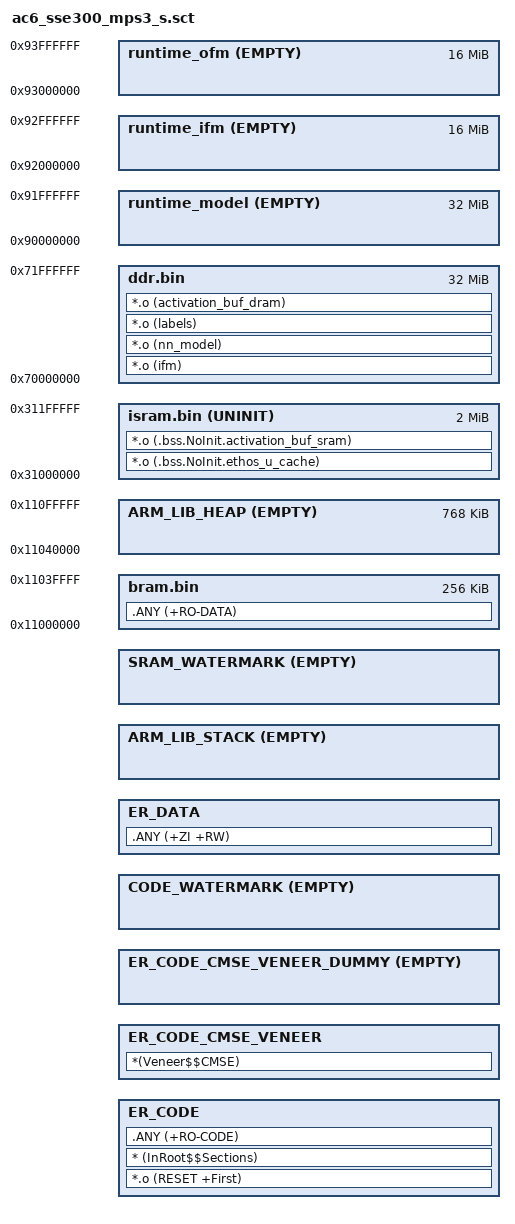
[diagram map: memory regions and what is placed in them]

;/*
; * Copyright (c) 2018-2021 Arm Limited. All rights reserved.
; *
; * Licensed under the Apache License, Version 2.0 (the "License");
; * you may not use this file except in compliance with the License.
; * You may obtain a copy of the License at
; *
; *     http://www.apache.org/licenses/LICENSE-2.0
; *
; * Unless required by applicable law or agreed to in writing, software
; * distributed under the License is distributed on an "AS IS" BASIS,
; * WITHOUT WARRANTIES OR CONDITIONS OF ANY KIND, either express or implied.
; * See the License for the specific language governing permissions and
; * limitations under the License.
; *
; */

;#include "region_defs.h"

LR_CODE S_CODE_START {
    ER_CODE S_CODE_START {
        *.o (RESET +First)
        /* different test vectors */
        * (InRoot$$Sections)
        .ANY (+RO-CODE)
        
    }

    /*
     * Place the CMSE Veneers (containing the SG instruction) after the code, in
     * a separate 32 bytes aligned region so that the SAU can programmed to just
     * set this region as Non-Secure Callable. The maximum size of this
     * executable region makes it only used the space left over by the ER_CODE
     * region so that you can rely on code+veneer size combined will not exceed
     * the S_CODE_SIZE value. We also substract from the available space the
     * area used to align this section on 32 bytes boundary (for SAU conf).
     */
    ER_CODE_CMSE_VENEER +0 ALIGN 32 {
        *(Veneer$$CMSE)
    }
    /*
     * This dummy region ensures that the next one will be aligned on a 32 bytes
     * boundary, so that the following region will not be mistakenly configured
     * as Non-Secure Callable by the SAU.
     */
    ER_CODE_CMSE_VENEER_DUMMY +0 ALIGN 32 EMPTY 0 {}

    /* This empty, zero long execution region is here to mark the limit address
     * of the last execution region that is allocated in SRAM.
     */
    CODE_WATERMARK +0 EMPTY 0x0 {
    }
    /* Make sure that the sections allocated in the SRAM does not exceed the
     * size of the SRAM available.
     */
    ScatterAssert(ImageLimit(CODE_WATERMARK) <= S_CODE_START + S_CODE_SIZE)

    ER_DATA S_DATA_START {
        .ANY (+ZI +RW)
    }


    ARM_LIB_STACK +0 ALIGN 32 EMPTY STACK_SIZE {   ; Reserve empty region for stack
    }

    /* This empty, zero long execution region is here to mark the limit address
     * of the last execution region that is allocated in SRAM.
     */
    SRAM_WATERMARK +0 EMPTY 0x0 {
    }
    /* Make sure that the sections allocated in the SRAM does not exceed the
     * size of the SRAM available.
     */
    ScatterAssert(ImageLimit(SRAM_WATERMARK) <= S_DATA_START + S_DATA_SIZE)

    isram.bin       0x31000000  UNINIT ALIGN 16 0x00200000
    {
        ; Cache area (if used)
        *.o (.bss.NoInit.ethos_u_cache)

        ; activation buffers a.k.a tensor arena when
        ; memory mode sram only or shared sram
        *.o (.bss.NoInit.activation_buf_sram)
    }
}

LOAD_REGION_1       0x70000000                  0x02000000
{
    ;-----------------------------------------------------
    ; 32 MiB of DDR space for neural network model,
    ; input vectors and labels. If the activation buffer
    ; size required by the network is bigger than the
    ; SRAM size available, it is accommodated here.
    ;-----------------------------------------------------
    ddr.bin        0x70000000 ALIGN 16         0x02000000
    {
        ; nn model s baked in input matrices
        *.o (ifm)

        ; nn model s default space
        *.o (nn_model)

        ; labels
        *.o (labels)

        ; activation buffers a.k.a tensor arena when memory mode dedicated sram
        *.o (activation_buf_dram)
    }

    ;-----------------------------------------------------
    ; First 256kiB of BRAM (FPGA SRAM) used for RO data.
    ; Note: Total BRAM size available is 1MiB.
    ;-----------------------------------------------------
    bram.bin        0x11000000          ALIGN 8 0x00040000
    {
        ; RO data (incl. unwinding tables for debugging)
        .ANY (+RO-DATA)
    }

    ;-----------------------------------------------------
    ; 768 KiB of remaining part of the 1MiB BRAM used as
    ; heap space.
    ;-----------------------------------------------------
    ARM_LIB_HEAP    0x11040000 EMPTY ALIGN 8    0x000C0000
    {}

    ;-----------------------------------------------------
    ; The following regions are for use by the FVP to
    ; allow loading or dumping of dynamic data into or
    ; from the memory. These regions are mentioned in
    ; the CMake subsystem profile. Do not change the
    ; addresses and sizes below in isolation.
    ;-----------------------------------------------------
    ; 32 MiB of model space for run-time load of model
    ;-----------------------------------------------------
    runtime_model   0x90000000 EMPTY ALIGN 16   0x02000000
    {}

    ;-----------------------------------------------------
    ; 16 MiB of IFM space for run-time loading (FVP only)
    ;-----------------------------------------------------
    runtime_ifm     0x92000000 EMPTY ALIGN 16   0x01000000
    {}

    ;-----------------------------------------------------
    ; 16 MiB of OFM space for run-time loading (FVP only)
    ;-----------------------------------------------------
    runtime_ofm     0x93000000 EMPTY ALIGN 16   0x01000000
    {}
}
